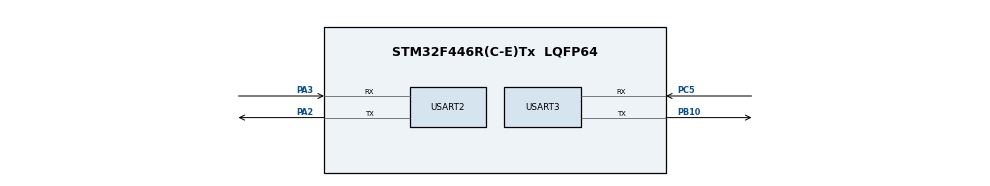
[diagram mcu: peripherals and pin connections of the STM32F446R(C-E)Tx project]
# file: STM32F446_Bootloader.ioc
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Mcu.Family=STM32F4
Mcu.Name=STM32F446R(C-E)Tx
Mcu.Package=LQFP64
NVIC.PriorityGroup=NVIC_PRIORITYGROUP_4
NVIC.USART2_IRQn=true\:0\:0\:false\:false\:true\:true\:true
NVIC.USART3_IRQn=true\:0\:0\:false\:false\:true\:true\:true
PA13.Mode=Serial_Wire
PA13.Signal=SYS_JTMS-SWDIO
PA14.Mode=Serial_Wire
PA14.Signal=SYS_JTCK-SWCLK
PA2.Mode=Asynchronous
PA2.Signal=USART2_TX
PA3.Mode=Asynchronous
PA3.Signal=USART2_RX
PB10.Mode=Asynchronous
PB10.Signal=USART3_TX
PC14-OSC32_IN.Mode=LSE-External-Oscillator
PC14-OSC32_IN.Signal=RCC_OSC32_IN
PC15-OSC32_OUT.Mode=LSE-External-Oscillator
PC15-OSC32_OUT.Signal=RCC_OSC32_OUT
PC5.Mode=Asynchronous
PC5.Signal=USART3_RX
PH0-OSC_IN.Mode=HSE-External-Clock-Source
PH0-OSC_IN.Signal=RCC_OSC_IN
PH1-OSC_OUT.Mode=HSE-External-Clock-Source
PH1-OSC_OUT.Signal=RCC_OSC_OUT
ProjectManager.HeapSize=0x200
ProjectManager.StackSize=0x400
ProjectManager.TargetToolchain=STM32CubeIDE
RCC.CortexFreq_Value=16000000
RCC.USBFreq_Value=96000000
RCC.VCOOutputFreq_Value=192000000
USART2.VirtualMode=VM_ASYNC
USART3.VirtualMode=VM_ASYNC
VP_CRC_VS_CRC.Mode=CRC_Activate
board=custom

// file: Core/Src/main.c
/* USER CODE BEGIN Header */
/**
  ******************************************************************************
  * @file           : main.c
  * @brief          : Main program body
  ******************************************************************************
  * @attention
  *
  * <h2><center>&copy; Copyright (c) 2020 STMicroelectronics.
  * All rights reserved.</center></h2>
  *
  * This software component is licensed by ST under BSD 3-Clause license,
  * the "License"; You may not use this file except in compliance with the
  * License. You may obtain a copy of the License at:
  *                        opensource.org/licenses/BSD-3-Clause
  *
  ******************************************************************************
  */
/* USER CODE END Header */

#include "main.h"

/* USER CODE BEGIN Includes */

#include <string.h>
#include <stdarg.h>
#include <stdint.h>

#include "bootloader.h"

/* USER CODE END Includes */

/* USER CODE BEGIN PD */

#define JUMP_TO_APP(ADDRESS)  						{((void (*)()) (*(uint32_t*)ADDRESS)) ();}
/* USER CODE END PD */

CRC_HandleTypeDef hcrc;

UART_HandleTypeDef huart2;
UART_HandleTypeDef huart3;

/* USER CODE BEGIN PV */
uint8_t pData[] = "Hello, World!";
/* USER CODE END PV */

void SystemClock_Config(void);
static void MX_GPIO_Init(void);
static void MX_CRC_Init(void);
static void MX_USART2_UART_Init(void);
static void MX_USART3_UART_Init(void);

int main(void)
{

  /* MCU Configuration--------------------------------------------------------*/

  /* Reset of all peripherals, Initializes the Flash interface and the Systick. */
  HAL_Init();

  /* Configure the system clock */
  SystemClock_Config();

  /* Initialize all configured peripherals */
  MX_GPIO_Init();
  MX_CRC_Init();
  MX_USART2_UART_Init();
  MX_USART3_UART_Init();

  /* Infinite loop */
  /* USER CODE BEGIN WHILE */

  printmsg("Bootloader Started\r\n");

  while (1)
  {
    /* USER CODE END WHILE */

	  if (HAL_GPIO_ReadPin(GPIOC, GPIO_PIN_13) == 0)
	  {
		  printmsg("Button Pressed... BL MODE\r\nPress Reset in the Board to Exit\r\n");
		  while(1)
		  {
			  bootloader_uart_read_data();
		  }
	  }
	  else
	  {
		  bootloader_jump_to_user_application();
	  }
	  HAL_Delay(1000);
  }
}

void SystemClock_Config(void)
{
  RCC_OscInitTypeDef RCC_OscInitStruct = {0};
  RCC_ClkInitTypeDef RCC_ClkInitStruct = {0};

  /** Configure the main internal regulator output voltage
  */
  __HAL_RCC_PWR_CLK_ENABLE();
  __HAL_PWR_VOLTAGESCALING_CONFIG(PWR_REGULATOR_VOLTAGE_SCALE3);
  /** Initializes the CPU, AHB and APB busses clocks
  */
  RCC_OscInitStruct.OscillatorType = RCC_OSCILLATORTYPE_HSI;
  RCC_OscInitStruct.HSIState = RCC_HSI_ON;
  RCC_OscInitStruct.HSICalibrationValue = RCC_HSICALIBRATION_DEFAULT;
  RCC_OscInitStruct.PLL.PLLState = RCC_PLL_NONE;
  if (HAL_RCC_OscConfig(&RCC_OscInitStruct) != HAL_OK)
  {
    Error_Handler();
  }
  /** Initializes the CPU, AHB and APB busses clocks
  */
  RCC_ClkInitStruct.ClockType = RCC_CLOCKTYPE_HCLK|RCC_CLOCKTYPE_SYSCLK
                              |RCC_CLOCKTYPE_PCLK1|RCC_CLOCKTYPE_PCLK2;
  RCC_ClkInitStruct.SYSCLKSource = RCC_SYSCLKSOURCE_HSI;
  RCC_ClkInitStruct.AHBCLKDivider = RCC_SYSCLK_DIV1;
  RCC_ClkInitStruct.APB1CLKDivider = RCC_HCLK_DIV1;
  RCC_ClkInitStruct.APB2CLKDivider = RCC_HCLK_DIV1;

  if (HAL_RCC_ClockConfig(&RCC_ClkInitStruct, FLASH_LATENCY_0) != HAL_OK)
  {
    Error_Handler();
  }
}

static void MX_CRC_Init(void)
{

  hcrc.Instance = CRC;
  if (HAL_CRC_Init(&hcrc) != HAL_OK)
  {
    Error_Handler();
  }

}

static void MX_USART2_UART_Init(void)
{

  huart2.Instance = USART2;
  huart2.Init.BaudRate = 115200;
  huart2.Init.WordLength = UART_WORDLENGTH_8B;
  huart2.Init.StopBits = UART_STOPBITS_1;
  huart2.Init.Parity = UART_PARITY_NONE;
  huart2.Init.Mode = UART_MODE_TX_RX;
  huart2.Init.HwFlowCtl = UART_HWCONTROL_NONE;
  huart2.Init.OverSampling = UART_OVERSAMPLING_16;
  if (HAL_UART_Init(&huart2) != HAL_OK)
  {
    Error_Handler();
  }

}

static void MX_USART3_UART_Init(void)
{

  huart3.Instance = USART3;
  huart3.Init.BaudRate = 115200;
  huart3.Init.WordLength = UART_WORDLENGTH_8B;
  huart3.Init.StopBits = UART_STOPBITS_1;
  huart3.Init.Parity = UART_PARITY_NONE;
  huart3.Init.Mode = UART_MODE_TX_RX;
  huart3.Init.HwFlowCtl = UART_HWCONTROL_NONE;
  huart3.Init.OverSampling = UART_OVERSAMPLING_16;
  if (HAL_UART_Init(&huart3) != HAL_OK)
  {
    Error_Handler();
  }

}

static void MX_GPIO_Init(void)
{

  /* GPIO Ports Clock Enable */
  __HAL_RCC_GPIOC_CLK_ENABLE();
  __HAL_RCC_GPIOH_CLK_ENABLE();
  __HAL_RCC_GPIOA_CLK_ENABLE();
  __HAL_RCC_GPIOB_CLK_ENABLE();

  GPIO_InitTypeDef GPIO_InitStruct;
  GPIO_InitStruct.Pin = GPIO_PIN_13;
  GPIO_InitStruct.Mode = GPIO_MODE_INPUT;
  GPIO_InitStruct.Pull = GPIO_NOPULL;
  GPIO_InitStruct.Speed = GPIO_SPEED_FREQ_LOW;
  HAL_GPIO_Init(GPIOC, &GPIO_InitStruct);
}

void Error_Handler(void)
{
}

/************************ (C) COPYRIGHT STMicroelectronics *****END OF FILE****/
